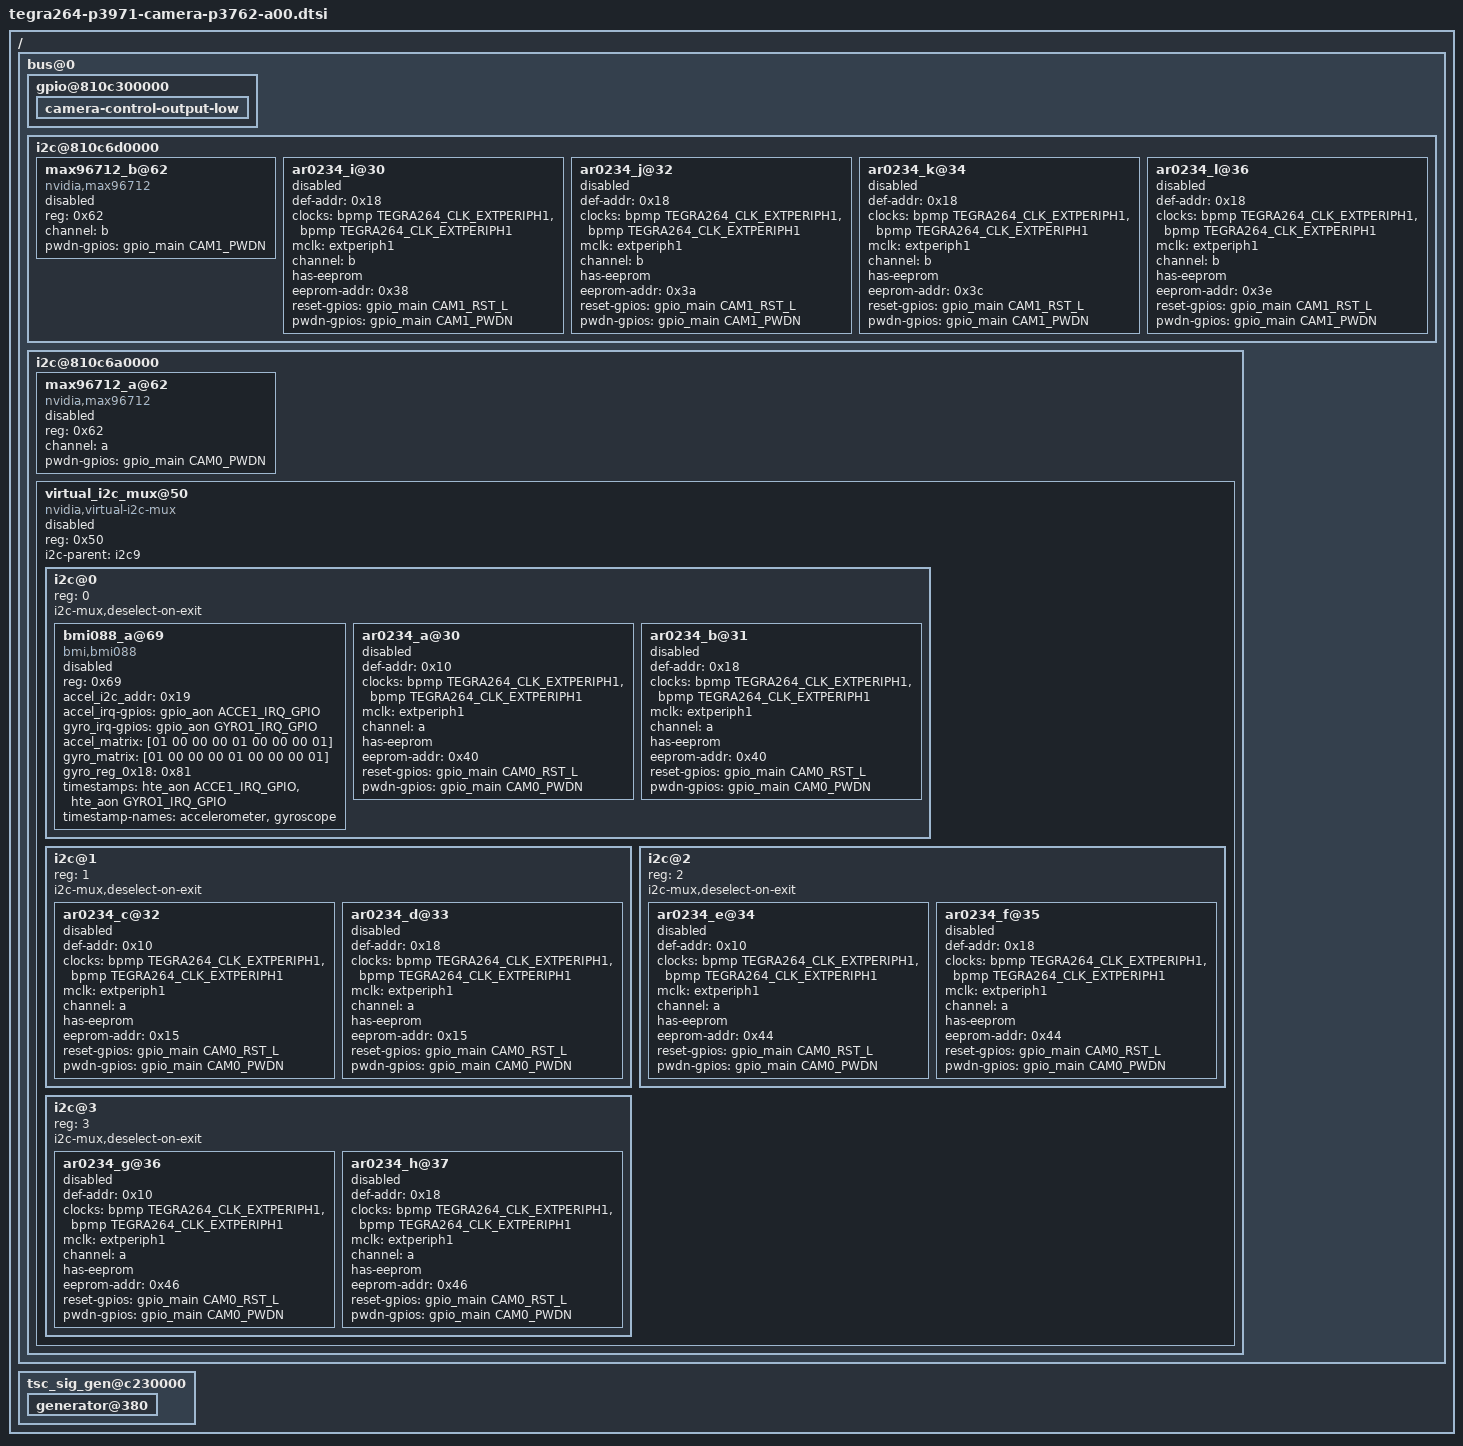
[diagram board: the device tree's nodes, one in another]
// SPDX-License-Identifier: GPL-2.0-only
// SPDX-FileCopyrightText: Copyright (c) 2024-2025, NVIDIA CORPORATION & AFFILIATES. All rights reserved.

#include "tegra264-camera-p3762-a00.dtsi"
#include <dt-bindings/gpio/tegra264-gpio.h>
#include <dt-bindings/clock/tegra264-clk.h>

/* camera control gpio definitions */
#define CAM0_RST_L      TEGRA264_MAIN_GPIO(V, 2)
#define CAM0_PWDN       TEGRA264_MAIN_GPIO(AL, 1)
#define CAM1_RST_L      TEGRA264_MAIN_GPIO(Q, 3)
#define CAM1_PWDN       TEGRA264_MAIN_GPIO(Q, 2)

/* Not used - #define PWR_EN          TEGRA264_MAIN_GPIO(AC, 7) */
#define ACCE1_IRQ_GPIO  TEGRA264_AON_GPIO(CC, 7)
#define GYRO1_IRQ_GPIO  TEGRA264_AON_GPIO(DD, 0)

/ {
	fragment-camera-hawk-owl@0 {
		target-path = "/";
		__overlay__ {
			bus@0 {
				/* set camera gpio direction to output */
				gpio@810c300000 {
					camera-control-output-low {
					};
				};
				i2c@810c6d0000 {
					max96712_b@62 {
						compatible = "nvidia,max96712";
						reg = <0x62>;
						channel = "b";
						pwdn-gpios = <&gpio_main CAM1_PWDN GPIO_ACTIVE_HIGH>;
						status = "disabled";
					};
					ar0234_i@30 {
						status = "disabled";
						def-addr = <0x18>;
						/* Define any required hw resources needed by driver */
						/* ie. clocks, io pins, power sources */
						clocks = <&bpmp TEGRA264_CLK_EXTPERIPH1>,
								<&bpmp TEGRA264_CLK_EXTPERIPH1>;
						clock-names = "extperiph1", "pllp_grtba";
						mclk = "extperiph1";
						channel = "b";
						has-eeprom;
						eeprom-addr = <0x38>;
						reset-gpios = <&gpio_main CAM1_RST_L GPIO_ACTIVE_HIGH>;
						pwdn-gpios = <&gpio_main CAM1_PWDN GPIO_ACTIVE_HIGH>;
						/* pwr-gpios = <&gpio_main PWR_EN GPIO_ACTIVE_HIGH>; */
					};
					ar0234_j@32 {
						status = "disabled";
						def-addr = <0x18>;
						/* Define any required hw resources needed by driver */
						/* ie. clocks, io pins, power sources */
						clocks = <&bpmp TEGRA264_CLK_EXTPERIPH1>,
								<&bpmp TEGRA264_CLK_EXTPERIPH1>;
						clock-names = "extperiph1", "pllp_grtba";
						mclk = "extperiph1";
						channel = "b";
						has-eeprom;
						eeprom-addr = <0x3a>;
						reset-gpios = <&gpio_main CAM1_RST_L GPIO_ACTIVE_HIGH>;
						pwdn-gpios = <&gpio_main CAM1_PWDN GPIO_ACTIVE_HIGH>;
						/* pwr-gpios = <&gpio_main PWR_EN GPIO_ACTIVE_HIGH>; */
					};
					ar0234_k@34 {
						status = "disabled";
						def-addr = <0x18>;
						/* Define any required hw resources needed by driver */
						/* ie. clocks, io pins, power sources */
						clocks = <&bpmp TEGRA264_CLK_EXTPERIPH1>,
								<&bpmp TEGRA264_CLK_EXTPERIPH1>;
						clock-names = "extperiph1", "pllp_grtba";
						mclk = "extperiph1";
						channel = "b";
						has-eeprom;
						eeprom-addr = <0x3c>;
						reset-gpios = <&gpio_main CAM1_RST_L GPIO_ACTIVE_HIGH>;
						pwdn-gpios = <&gpio_main CAM1_PWDN GPIO_ACTIVE_HIGH>;
						/* pwr-gpios = <&gpio_main PWR_EN GPIO_ACTIVE_HIGH>; */
					};
					ar0234_l@36 {
						status = "disabled";
						def-addr = <0x18>;
						/* Define any required hw resources needed by driver */
						/* ie. clocks, io pins, power sources */
						clocks = <&bpmp TEGRA264_CLK_EXTPERIPH1>,
								<&bpmp TEGRA264_CLK_EXTPERIPH1>;
						clock-names = "extperiph1", "pllp_grtba";
						mclk = "extperiph1";
						channel = "b";
						has-eeprom;
						eeprom-addr = <0x3e>;
						reset-gpios = <&gpio_main CAM1_RST_L GPIO_ACTIVE_HIGH>;
						pwdn-gpios = <&gpio_main CAM1_PWDN GPIO_ACTIVE_HIGH>;
						/* pwr-gpios = <&gpio_main PWR_EN GPIO_ACTIVE_HIGH>; */
					};
				};
				i2c@810c6a0000 {
					max96712_a@62 {
						compatible = "nvidia,max96712";
						reg = <0x62>;
						channel = "a";
						pwdn-gpios = <&gpio_main CAM0_PWDN GPIO_ACTIVE_HIGH>;
						status = "disabled";
					};
					virtual_i2c_mux@50 {
						reg = <0x50>;
						compatible = "nvidia,virtual-i2c-mux";
						#address-cells = <1>;
						#size-cells = <0>;
						i2c-parent = <&i2c9>;
						status = "disabled";

						i2c@0 {
							reg = <0>;
							i2c-mux,deselect-on-exit;
							#address-cells = <1>;
							#size-cells = <0>;

							bmi088_a@69 {
								compatible = "bmi,bmi088";
								reg = <0x69>;
								accel_i2c_addr = <0x19>;
								accel_irq-gpios = <&gpio_aon ACCE1_IRQ_GPIO GPIO_ACTIVE_HIGH>;
								gyro_irq-gpios = <&gpio_aon GYRO1_IRQ_GPIO GPIO_ACTIVE_HIGH>;
								accel_matrix = [01 00 00 00 01 00 00 00 01];
								gyro_matrix = [01 00 00 00 01 00 00 00 01];
								gyro_reg_0x18 = <0x81>;
								timestamps = <&hte_aon ACCE1_IRQ_GPIO>, <&hte_aon GYRO1_IRQ_GPIO>;
								timestamp-names = "accelerometer", "gyroscope";
								status = "disabled";
							};
							ar0234_a@30 {
								status = "disabled";
								def-addr = <0x10>;
								/* Define any required hw resources needed by driver */
								/* ie. clocks, io pins, power sources */
								clocks = <&bpmp TEGRA264_CLK_EXTPERIPH1>,
										<&bpmp TEGRA264_CLK_EXTPERIPH1>;
								clock-names = "extperiph1", "pllp_grtba";
								mclk = "extperiph1";
								channel = "a";
								has-eeprom;
								eeprom-addr = <0x40>;
								reset-gpios = <&gpio_main CAM0_RST_L GPIO_ACTIVE_HIGH>;
								pwdn-gpios = <&gpio_main CAM0_PWDN GPIO_ACTIVE_HIGH>;
								/* pwr-gpios = <&gpio_main PWR_EN GPIO_ACTIVE_HIGH>; */
							};
							ar0234_b@31 {
								status = "disabled";
								def-addr = <0x18>;
								/* Define any required hw resources needed by driver */
								/* ie. clocks, io pins, power sources */
								clocks = <&bpmp TEGRA264_CLK_EXTPERIPH1>,
										<&bpmp TEGRA264_CLK_EXTPERIPH1>;
								clock-names = "extperiph1", "pllp_grtba";
								mclk = "extperiph1";
								channel = "a";
								has-eeprom;
								eeprom-addr = <0x40>;
								reset-gpios = <&gpio_main CAM0_RST_L GPIO_ACTIVE_HIGH>;
								pwdn-gpios = <&gpio_main CAM0_PWDN GPIO_ACTIVE_HIGH>;
								/* pwr-gpios = <&gpio_main PWR_EN GPIO_ACTIVE_HIGH>; */
							};
						};
						i2c@1 {
							reg = <1>;
							i2c-mux,deselect-on-exit;
							#address-cells = <1>;
							#size-cells = <0>;
							ar0234_c@32 {
								status = "disabled";
								def-addr = <0x10>;
								/* Define any required hw resources needed by driver */
								/* ie. clocks, io pins, power sources */
								clocks = <&bpmp TEGRA264_CLK_EXTPERIPH1>,
										<&bpmp TEGRA264_CLK_EXTPERIPH1>;
								clock-names = "extperiph1", "pllp_grtba";
								mclk = "extperiph1";
								channel = "a";
								has-eeprom;
								eeprom-addr = <0x15>;
								reset-gpios = <&gpio_main CAM0_RST_L GPIO_ACTIVE_HIGH>;
								pwdn-gpios = <&gpio_main CAM0_PWDN GPIO_ACTIVE_HIGH>;
								/* pwr-gpios = <&gpio_main PWR_EN GPIO_ACTIVE_HIGH>; */
							};
							ar0234_d@33 {
								status = "disabled";
								def-addr = <0x18>;
								/* Define any required hw resources needed by driver */
								/* ie. clocks, io pins, power sources */
								clocks = <&bpmp TEGRA264_CLK_EXTPERIPH1>,
										<&bpmp TEGRA264_CLK_EXTPERIPH1>;
								clock-names = "extperiph1", "pllp_grtba";
								mclk = "extperiph1";
								channel = "a";
								has-eeprom;
								eeprom-addr = <0x15>;
								reset-gpios = <&gpio_main CAM0_RST_L GPIO_ACTIVE_HIGH>;
								pwdn-gpios = <&gpio_main CAM0_PWDN GPIO_ACTIVE_HIGH>;
								/* pwr-gpios = <&gpio_main PWR_EN GPIO_ACTIVE_HIGH>; */
							};
						};
						i2c@2 {
							reg = <2>;
							i2c-mux,deselect-on-exit;
							#address-cells = <1>;
							#size-cells = <0>;
							ar0234_e@34 {
								status = "disabled";
								def-addr = <0x10>;
								/* Define any required hw resources needed by driver */
								/* ie. clocks, io pins, power sources */
								clocks = <&bpmp TEGRA264_CLK_EXTPERIPH1>,
										<&bpmp TEGRA264_CLK_EXTPERIPH1>;
								clock-names = "extperiph1", "pllp_grtba";
								mclk = "extperiph1";
								channel = "a";
								has-eeprom;
								eeprom-addr = <0x44>;
								reset-gpios = <&gpio_main CAM0_RST_L GPIO_ACTIVE_HIGH>;
								pwdn-gpios = <&gpio_main CAM0_PWDN GPIO_ACTIVE_HIGH>;
								/* pwr-gpios = <&gpio_main PWR_EN GPIO_ACTIVE_HIGH>; */
							};
							ar0234_f@35 {
								status = "disabled";
								def-addr = <0x18>;
								/* Define any required hw resources needed by driver */
								/* ie. clocks, io pins, power sources */
								clocks = <&bpmp TEGRA264_CLK_EXTPERIPH1>,
										<&bpmp TEGRA264_CLK_EXTPERIPH1>;
								clock-names = "extperiph1", "pllp_grtba";
								mclk = "extperiph1";
								channel = "a";
								has-eeprom;
								eeprom-addr = <0x44>;
								reset-gpios = <&gpio_main CAM0_RST_L GPIO_ACTIVE_HIGH>;
								pwdn-gpios = <&gpio_main CAM0_PWDN GPIO_ACTIVE_HIGH>;
								/* pwr-gpios = <&gpio_main PWR_EN GPIO_ACTIVE_HIGH>; */
							};
						};
						i2c@3 {
							reg = <3>;
							i2c-mux,deselect-on-exit;
							#address-cells = <1>;
							#size-cells = <0>;
							ar0234_g@36 {
								status = "disabled";
								def-addr = <0x10>;
								/* Define any required hw resources needed by driver */
								/* ie. clocks, io pins, power sources */
								clocks = <&bpmp TEGRA264_CLK_EXTPERIPH1>,
										<&bpmp TEGRA264_CLK_EXTPERIPH1>;
								clock-names = "extperiph1", "pllp_grtba";
								mclk = "extperiph1";
								channel = "a";
								has-eeprom;
								eeprom-addr = <0x46>;
								reset-gpios = <&gpio_main CAM0_RST_L GPIO_ACTIVE_HIGH>;
								pwdn-gpios = <&gpio_main CAM0_PWDN GPIO_ACTIVE_HIGH>;
								/* pwr-gpios = <&gpio_main PWR_EN GPIO_ACTIVE_HIGH>; */
							};
							ar0234_h@37 {
								status = "disabled";
								def-addr = <0x18>;
								/* Define any required hw resources needed by driver */
								/* ie. clocks, io pins, power sources */
								clocks = <&bpmp TEGRA264_CLK_EXTPERIPH1>,
										<&bpmp TEGRA264_CLK_EXTPERIPH1>;
								clock-names = "extperiph1", "pllp_grtba";
								mclk = "extperiph1";
								channel = "a";
								has-eeprom;
								eeprom-addr = <0x46>;
								reset-gpios = <&gpio_main CAM0_RST_L GPIO_ACTIVE_HIGH>;
								pwdn-gpios = <&gpio_main CAM0_PWDN GPIO_ACTIVE_HIGH>;
								/* pwr-gpios = <&gpio_main PWR_EN GPIO_ACTIVE_HIGH>; */
							};
						};
					};
				};
			};
		};
	};

	fragment-cam-cdi-tsc@0 {
		target-path = "/";
		__overlay__ {
			tsc_sig_gen@c230000 {
				status = "okay";
				generator@380 {
					status = "okay";
				};
			};
		};
	};
};
